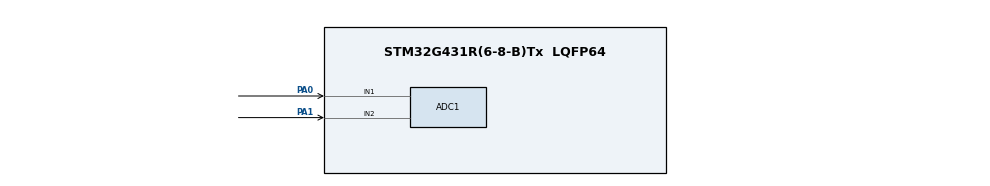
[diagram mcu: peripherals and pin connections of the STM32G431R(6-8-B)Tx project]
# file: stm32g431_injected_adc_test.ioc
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ADC1.Channel-4\#ChannelRegularConversion=ADC_CHANNEL_1
ADC1.Channel-5\#ChannelRegularConversion=ADC_CHANNEL_2
ADC1.EnableInjectedConversion=ENABLE
ADC1.EnableRegularConversion=ENABLE
ADC1.InjNumberOfConversion=2
ADC1.InjectedChannel-2\#ChannelInjectedConversion=ADC_CHANNEL_1
ADC1.InjectedChannel-3\#ChannelInjectedConversion=ADC_CHANNEL_1
ADC1.InjectedOffsetNumber-2\#ChannelInjectedConversion=ADC_OFFSET_NONE
ADC1.InjectedOffsetNumber-3\#ChannelInjectedConversion=ADC_OFFSET_NONE
ADC1.InjectedRank-2\#ChannelInjectedConversion=1
ADC1.InjectedRank-3\#ChannelInjectedConversion=2
ADC1.InjectedSamplingTime-2\#ChannelInjectedConversion=ADC_SAMPLETIME_47CYCLES_5
ADC1.InjectedSamplingTime-3\#ChannelInjectedConversion=ADC_SAMPLETIME_47CYCLES_5
ADC1.NbrOfConversion=2
ADC1.NbrOfConversionFlag=1
ADC1.OffsetNumber-4\#ChannelRegularConversion=ADC_OFFSET_NONE
ADC1.OffsetNumber-5\#ChannelRegularConversion=ADC_OFFSET_NONE
ADC1.Rank-4\#ChannelRegularConversion=1
ADC1.Rank-5\#ChannelRegularConversion=2
ADC1.Rank2_Channel=ADC_CHANNEL_1
ADC1.SamplingTime-4\#ChannelRegularConversion=ADC_SAMPLETIME_47CYCLES_5
ADC1.SamplingTime-5\#ChannelRegularConversion=ADC_SAMPLETIME_47CYCLES_5
ADC1.master=1
Mcu.Family=STM32G4
Mcu.Name=STM32G431R(6-8-B)Tx
Mcu.Package=LQFP64
NVIC.PriorityGroup=NVIC_PRIORITYGROUP_4
PA0.Mode=IN1-Single-Ended
PA0.Signal=ADC1_IN1
PA1.Mode=IN2-Single-Ended
PA1.Signal=ADC1_IN2
PA13.Mode=Serial_Wire
PA13.Signal=SYS_JTMS-SWDIO
PA14.Mode=Serial_Wire
PA14.Signal=SYS_JTCK-SWCLK
PF0-OSC_IN.Mode=HSE-External-Oscillator
PF0-OSC_IN.Signal=RCC_OSC_IN
PF1-OSC_OUT.Mode=HSE-External-Oscillator
PF1-OSC_OUT.Signal=RCC_OSC_OUT
ProjectManager.HeapSize=0x200
ProjectManager.StackSize=0x400
ProjectManager.TargetToolchain=MDK-ARM V5
RCC.ADC12Freq_Value=170000000
RCC.AHBFreq_Value=170000000
RCC.APB1Freq_Value=170000000
RCC.APB1TimFreq_Value=170000000
RCC.APB2Freq_Value=170000000
RCC.APB2TimFreq_Value=170000000
RCC.CortexFreq_Value=170000000
RCC.EXTERNAL_CLOCK_VALUE=12288000
RCC.HCLKFreq_Value=170000000
RCC.HSE_VALUE=24000000
RCC.HSI48_VALUE=48000000
RCC.HSI_VALUE=16000000
RCC.LSE_VALUE=32768
RCC.PLLM=RCC_PLLM_DIV4
RCC.PLLN=85
RCC.SYSCLKFreq_VALUE=170000000
RCC.SYSCLKSource=RCC_SYSCLKSOURCE_PLLCLK
RCC.USBFreq_Value=170000000
RCC.VCOOutputFreq_Value=340000000
VP_SYS_VS_DBSignals.Mode=DisableDeadBatterySignals
board=custom

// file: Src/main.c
/* USER CODE BEGIN Header */
/**
  ******************************************************************************
  * @file           : main.c
  * @brief          : Main program body
  ******************************************************************************
  * @attention
  *
  * <h2><center>&copy; Copyright (c) 2020 STMicroelectronics.
  * All rights reserved.</center></h2>
  *
  * This software component is licensed by ST under BSD 3-Clause license,
  * the "License"; You may not use this file except in compliance with the
  * License. You may obtain a copy of the License at:
  *                        opensource.org/licenses/BSD-3-Clause
  *
  ******************************************************************************
  */
/* USER CODE END Header */

#include "main.h"
#include "adc.h"
#include "gpio.h"

void SystemClock_Config(void);

/* USER CODE BEGIN 0 */
 #define VAR_CONVERTED_DATA_INIT_VALUE    (__LL_ADC_DIGITAL_SCALE(LL_ADC_RESOLUTION_12B) + 1)
__IO uint16_t uhADCxConvertedData1 = VAR_CONVERTED_DATA_INIT_VALUE; /* ADC group regular conversion data */
__IO uint16_t uhADCxConvertedData2 = VAR_CONVERTED_DATA_INIT_VALUE; /* ADC group regular conversion data */

static void Activate_ADC(void);
/* USER CODE END 0 */

int main(void)
{

  /* MCU Configuration--------------------------------------------------------*/

  /* Reset of all peripherals, Initializes the Flash interface and the Systick. */

  LL_APB2_GRP1_EnableClock(LL_APB2_GRP1_PERIPH_SYSCFG);
  LL_APB1_GRP1_EnableClock(LL_APB1_GRP1_PERIPH_PWR);

  NVIC_SetPriorityGrouping(NVIC_PRIORITYGROUP_4);

  /* System interrupt init*/

  /** Disable the internal Pull-Up in Dead Battery pins of UCPD peripheral
  */
  LL_PWR_DisableDeadBatteryPD();

  /* Configure the system clock */
  SystemClock_Config();

  /* Initialize all configured peripherals */
  MX_GPIO_Init();
  MX_ADC1_Init();
  /* USER CODE BEGIN 2 */
	Activate_ADC();
  LL_ADC_DisableIT_JEOC(ADC1);
  LL_ADC_DisableIT_JEOS(ADC1);
  LL_ADC_DisableIT_EOC(ADC1);
  LL_ADC_DisableIT_EOS(ADC1);

//#define ADC_AUTDLY_ACTIVE
#ifdef ADC_AUTDLY_ACTIVE
	LL_ADC_SetLowPowerMode(ADC1, LL_ADC_LP_AUTOWAIT);
#endif
  /* USER CODE END 2 */

  /* Infinite loop */
  /* USER CODE BEGIN WHILE */
  while (1)
  {
#define ADC_REGULAR_CONV
#ifdef ADC_REGULAR_CONV
		if ((LL_ADC_IsEnabled(ADC1) == 1)               &&
				(LL_ADC_IsDisableOngoing(ADC1) == 0)        &&
				(LL_ADC_REG_IsConversionOngoing(ADC1) == 0)   )
		{
			LL_ADC_REG_StartConversion(ADC1);
		}
#ifdef ADC_AUTDLY_ACTIVE
		LL_mDelay(1);
#endif
		while (LL_ADC_IsActiveFlag_EOC(ADC1) == 0);
		uhADCxConvertedData1 = LL_ADC_REG_ReadConversionData12(ADC1);

#ifdef ADC_AUTDLY_ACTIVE
		LL_mDelay(1);
#endif

		while (LL_ADC_IsActiveFlag_EOC(ADC1) == 0);
		uhADCxConvertedData2 = LL_ADC_REG_ReadConversionData12(ADC1);

		while (LL_ADC_IsActiveFlag_EOS(ADC1) == 0);
		LL_ADC_ClearFlag_EOS(ADC1);
#else
		if ((LL_ADC_IsEnabled(ADC1) == 1) &&
				(LL_ADC_IsDisableOngoing(ADC1) == 0) &&
				(LL_ADC_INJ_IsConversionOngoing(ADC1) == 0))
		{
			LL_ADC_INJ_StartConversion(ADC1);
		}

		while (LL_ADC_IsActiveFlag_JEOS(ADC1) == 0);
		uhADCxConvertedData1 = LL_ADC_INJ_ReadConversionData12(ADC1, LL_ADC_INJ_RANK_1);
		uhADCxConvertedData2 = LL_ADC_INJ_ReadConversionData12(ADC1, LL_ADC_INJ_RANK_2);

		LL_ADC_ClearFlag_JEOS(ADC1);

		if(uhADCxConvertedData2 > 0x30)
		{
			//uhADCxConvertedData2 = 0;
		}
#endif
    /* USER CODE END WHILE */

  }
}

void SystemClock_Config(void)
{
  LL_FLASH_SetLatency(LL_FLASH_LATENCY_8);
  LL_PWR_EnableRange1BoostMode();
  LL_RCC_HSI_Enable();

   /* Wait till HSI is ready */
  while(LL_RCC_HSI_IsReady() != 1)
  {

  }
  LL_RCC_HSI_SetCalibTrimming(64);
  LL_RCC_PLL_ConfigDomain_SYS(LL_RCC_PLLSOURCE_HSI, LL_RCC_PLLM_DIV_4, 85, LL_RCC_PLLR_DIV_2);
  LL_RCC_PLL_EnableDomain_SYS();
  LL_RCC_PLL_Enable();

   /* Wait till PLL is ready */
  while(LL_RCC_PLL_IsReady() != 1)
  {

  }
  LL_RCC_SetSysClkSource(LL_RCC_SYS_CLKSOURCE_PLL);
  LL_RCC_SetAHBPrescaler(LL_RCC_SYSCLK_DIV_2);

   /* Wait till System clock is ready */
  while(LL_RCC_GetSysClkSource() != LL_RCC_SYS_CLKSOURCE_STATUS_PLL)
  {

  }
  /* Insure 1?s transition state at intermediate medium speed clock based on DWT */
  CoreDebug->DEMCR |= CoreDebug_DEMCR_TRCENA_Msk;
  DWT->CTRL |= DWT_CTRL_CYCCNTENA_Msk;
  DWT->CYCCNT = 0;
  while(DWT->CYCCNT < 100);
  /* Set AHB prescaler*/
  LL_RCC_SetAHBPrescaler(LL_RCC_SYSCLK_DIV_1);
  LL_RCC_SetAPB1Prescaler(LL_RCC_APB1_DIV_1);
  LL_RCC_SetAPB2Prescaler(LL_RCC_APB1_DIV_1);

  LL_Init1msTick(170000000);

  LL_SetSystemCoreClock(170000000);
  LL_RCC_SetADCClockSource(LL_RCC_ADC12_CLKSOURCE_SYSCLK);
}

/* USER CODE BEGIN 4 */
#define ADC_DELAY_CALIB_ENABLE_CPU_CYCLES  (LL_ADC_DELAY_CALIB_ENABLE_ADC_CYCLES * 32)
static void Activate_ADC(void)
{
  __IO uint32_t wait_loop_index = 0U;
  #if (USE_TIMEOUT == 1)
  uint32_t Timeout = 0U; /* Variable used for timeout management */
  #endif /* USE_TIMEOUT */

  /*## Operation on ADC hierarchical scope: ADC instance #####################*/

  /* Note: Hardware constraint (refer to description of the functions         */
  /*       below):                                                            */
  /*       On this STM32 serie, setting of these features is conditioned to   */
  /*       ADC state:                                                         */
  /*       ADC must be disabled.                                              */
  /* Note: In this example, all these checks are not necessary but are        */
  /*       implemented anyway to show the best practice usages                */
  /*       corresponding to reference manual procedure.                       */
  /*       Software can be optimized by removing some of these checks, if     */
  /*       they are not relevant considering previous settings and actions    */
  /*       in user application.                                               */
  if (LL_ADC_IsEnabled(ADC1) == 0)
  {
    /* Disable ADC deep power down (enabled by default after reset state) */
    LL_ADC_DisableDeepPowerDown(ADC1);

    /* Enable ADC internal voltage regulator */
    LL_ADC_EnableInternalRegulator(ADC1);

    /* Delay for ADC internal voltage regulator stabilization.                */
    /* Compute number of CPU cycles to wait for, from delay in us.            */
    /* Note: Variable divided by 2 to compensate partially                    */
    /*       CPU processing cycles (depends on compilation optimization).     */
    /* Note: If system core clock frequency is below 200kHz, wait time        */
    /*       is only a few CPU processing cycles.                             */
    wait_loop_index = ((LL_ADC_DELAY_INTERNAL_REGUL_STAB_US * (SystemCoreClock / (100000 * 2))) / 10);
    while(wait_loop_index != 0)
    {
      wait_loop_index--;
    }

    /* Run ADC self calibration */
    LL_ADC_StartCalibration(ADC1, LL_ADC_SINGLE_ENDED);

    /* Poll for ADC effectively calibrated */
    #if (USE_TIMEOUT == 1)
    Timeout = ADC_CALIBRATION_TIMEOUT_MS;
    #endif /* USE_TIMEOUT */

    while (LL_ADC_IsCalibrationOnGoing(ADC1) != 0)
    {
    #if (USE_TIMEOUT == 1)
      /* Check Systick counter flag to decrement the time-out value */
      if (LL_SYSTICK_IsActiveCounterFlag())
      {
        if(Timeout-- == 0)
        {
        /* Time-out occurred. Set LED to blinking mode */
        LED_Blinking(LED_BLINK_ERROR);
        }
      }
    #endif /* USE_TIMEOUT */
    }

    /* Delay between ADC end of calibration and ADC enable.                   */
    /* Note: Variable divided by 2 to compensate partially                    */
    /*       CPU processing cycles (depends on compilation optimization).     */
    wait_loop_index = (ADC_DELAY_CALIB_ENABLE_CPU_CYCLES >> 1);
    while(wait_loop_index != 0)
    {
      wait_loop_index--;
    }

    /* Enable ADC */
    LL_ADC_Enable(ADC1);

    /* Poll for ADC ready to convert */
    #if (USE_TIMEOUT == 1)
    Timeout = ADC_ENABLE_TIMEOUT_MS;
    #endif /* USE_TIMEOUT */

    while (LL_ADC_IsActiveFlag_ADRDY(ADC1) == 0)
    {
    #if (USE_TIMEOUT == 1)
      /* Check Systick counter flag to decrement the time-out value */
      if (LL_SYSTICK_IsActiveCounterFlag())
      {
        if(Timeout-- == 0)
        {
        /* Time-out occurred. Set LED to blinking mode */
        LED_Blinking(LED_BLINK_ERROR);
        }
      }
    #endif /* USE_TIMEOUT */
    }

    /* Note: ADC flag ADRDY is not cleared here to be able to check ADC       */
    /*       status afterwards.                                               */
    /*       This flag should be cleared at ADC Deactivation, before a new    */
    /*       ADC activation, using function "LL_ADC_ClearFlag_ADRDY()".       */
  }

  /*## Operation on ADC hierarchical scope: ADC group regular ################*/
  /* Note: No operation on ADC group regular performed here.                  */
  /*       ADC group regular conversions to be performed after this function  */
  /*       using function:                                                    */
  /*       "LL_ADC_REG_StartConversion();"                                    */

  /*## Operation on ADC hierarchical scope: ADC group injected ###############*/
  /* Note: No operation on ADC group injected performed here.                 */
  /*       ADC group injected conversions to be performed after this function */
  /*       using function:                                                    */
  /*       "LL_ADC_INJ_StartConversion();"                                    */

}

/* USER CODE END 4 */

void Error_Handler(void)
{
}

/************************ (C) COPYRIGHT STMicroelectronics *****END OF FILE****/
